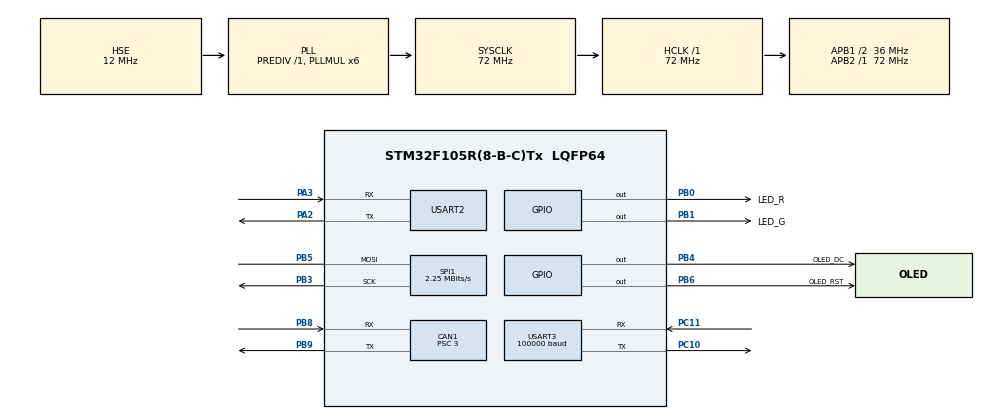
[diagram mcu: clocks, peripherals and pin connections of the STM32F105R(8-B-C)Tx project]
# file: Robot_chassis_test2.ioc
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CAN1.BS1=CAN_BS1_3TQ
CAN1.BS2=CAN_BS2_8TQ
CAN1.CalculateTimeBit=1000
CAN1.CalculateTimeQuantum=83.33333333333334
CAN1.Prescaler=3
Dma.Request0=USART3_RX
Dma.USART3_RX.0.Direction=DMA_PERIPH_TO_MEMORY
Dma.USART3_RX.0.Instance=DMA1_Channel3
Dma.USART3_RX.0.MemDataAlignment=DMA_MDATAALIGN_BYTE
Dma.USART3_RX.0.MemInc=DMA_MINC_ENABLE
Dma.USART3_RX.0.Mode=DMA_NORMAL
Dma.USART3_RX.0.PeriphDataAlignment=DMA_PDATAALIGN_BYTE
Dma.USART3_RX.0.PeriphInc=DMA_PINC_DISABLE
Dma.USART3_RX.0.Priority=DMA_PRIORITY_LOW
FREERTOS.Tasks01=vInitial_Task,2,128,Initial_Task,Default,NULL,Dynamic,NULL,NULL;vUser_Task,-1,128,User_Task,Default,NULL,Dynamic,NULL,NULL;vStartTask,-2,128,StartTask,Default,NULL,Dynamic,NULL,NULL;vChassis_Task,1,128,Chassis_Task,Default,NULL,Dynamic,NULL,NULL
Mcu.Family=STM32F1
Mcu.Name=STM32F105R(8-B-C)Tx
Mcu.Package=LQFP64
NVIC.CAN1_RX0_IRQn=true\:13\:0\:true\:false\:true\:true\:true\:true
NVIC.CAN1_TX_IRQn=true\:13\:0\:true\:false\:true\:true\:true\:true
NVIC.DMA1_Channel3_IRQn=true\:5\:0\:false\:false\:true\:true\:false\:true
NVIC.PriorityGroup=NVIC_PRIORITYGROUP_4
NVIC.USART3_IRQn=true\:6\:0\:true\:false\:true\:true\:true\:true
PA13.Mode=Serial_Wire
PA13.Signal=SYS_JTMS-SWDIO
PA14.Mode=Serial_Wire
PA14.Signal=SYS_JTCK-SWCLK
PA2.Mode=Asynchronous
PA2.Signal=USART2_TX
PA3.Mode=Asynchronous
PA3.Signal=USART2_RX
PB0.GPIO_Label=LED_R
PB0.Signal=GPIO_Output
PB1.GPIO_Label=LED_G
PB1.Signal=GPIO_Output
PB3.Mode=Simplex_Bidirectional_Master
PB3.Signal=SPI1_SCK
PB4.GPIO_Label=OLED_DC
PB4.Signal=GPIO_Output
PB5.Mode=Simplex_Bidirectional_Master
PB5.Signal=SPI1_MOSI
PB6.GPIO_Label=OLED_RST
PB6.Signal=GPIO_Output
PB8.Mode=Master
PB8.Signal=CAN1_RX
PB9.Mode=Master
PB9.Signal=CAN1_TX
PC10.Mode=Asynchronous
PC10.Signal=USART3_TX
PC11.Mode=Asynchronous
PC11.Signal=USART3_RX
PD0-OSC_IN.Mode=HSE-External-Oscillator
PD0-OSC_IN.Signal=RCC_OSC_IN
PD1-OSC_OUT.Mode=HSE-External-Oscillator
PD1-OSC_OUT.Signal=RCC_OSC_OUT
ProjectManager.HeapSize=0x200
ProjectManager.StackSize=0x400
ProjectManager.TargetToolchain=MDK-ARM V5
RCC.AHBFreq_Value=72000000
RCC.APB1CLKDivider=RCC_HCLK_DIV2
RCC.APB1Freq_Value=36000000
RCC.APB1TimFreq_Value=72000000
RCC.APB2Freq_Value=72000000
RCC.APB2TimFreq_Value=72000000
RCC.HCLKFreq_Value=72000000
RCC.HSE_VALUE=12000000
RCC.PLLMUL=RCC_PLL_MUL6
RCC.PLLSourceVirtual=RCC_PLLSOURCE_HSE
RCC.SYSCLKFreq_VALUE=72000000
RCC.SYSCLKSource=RCC_SYSCLKSOURCE_PLLCLK
RCC.USBFreq_Value=48000000
SPI1.BaudRatePrescaler=SPI_BAUDRATEPRESCALER_32
SPI1.CalculateBaudRate=2.25 MBits/s
SPI1.Direction=SPI_DIRECTION_1LINE
SPI1.Mode=SPI_MODE_MASTER
SPI1.VirtualType=VM_MASTER
USART2.VirtualMode=VM_ASYNC
USART3.BaudRate=100000
USART3.VirtualMode=VM_ASYNC
VP_FREERTOS_VS_CMSIS_V1.Mode=CMSIS_V1
board=custom

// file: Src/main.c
/* USER CODE BEGIN Header */
/**
  ******************************************************************************
  * @file           : main.c
  * @brief          : Main program body
  ******************************************************************************
  * @attention
  *
  * <h2><center>&copy; Copyright (c) 2019 STMicroelectronics.
  * All rights reserved.</center></h2>
  *
  * This software component is licensed by ST under Ultimate Liberty license
  * SLA0044, the "License"; You may not use this file except in compliance with
  * the License. You may obtain a copy of the License at:
  *                             www.st.com/SLA0044
  *
  ******************************************************************************
  */
/* USER CODE END Header */

#include "main.h"
#include "cmsis_os.h"
#include "can.h"
#include "dma.h"
#include "spi.h"
#include "usart.h"
#include "gpio.h"

/* USER CODE BEGIN Includes */
#include "Chassis_Task.h"
/* USER CODE END Includes */

void SystemClock_Config(void);
void MX_FREERTOS_Init(void);

int main(void)
{

  /* MCU Configuration--------------------------------------------------------*/

  /* Reset of all peripherals, Initializes the Flash interface and the Systick. */
  HAL_Init();

  /* Configure the system clock */
  SystemClock_Config();

  /* Initialize all configured peripherals */
  MX_GPIO_Init();
  MX_DMA_Init();
  MX_SPI1_Init();
  MX_USART2_UART_Init();
  MX_USART3_UART_Init();
  MX_CAN1_Init();
  /* USER CODE BEGIN 2 */

	can_user_init(&hcan1);															//can设备准备好
	HAL_UART_Receive_IT_IDLE(&huart3,UART_Buffer,100);   //启动串口接收

//	for (uint8_t i = 0; i < 7; i++)
//  {
//    pid_init(&motor_pid[i], 1.5, 0.1, 0, 30000, 30000); //init pid parameter, kp=40, ki=3, kd=0, output limit = 30000
//  }
  /* USER CODE END 2 */

  /* Call init function for freertos objects (in freertos.c) */
  MX_FREERTOS_Init();

  /* Start scheduler */
  osKernelStart();

  /* We should never get here as control is now taken by the scheduler */

  /* Infinite loop */
  while (1)
  {

  }
}

void SystemClock_Config(void)
{
  RCC_OscInitTypeDef RCC_OscInitStruct = {0};
  RCC_ClkInitTypeDef RCC_ClkInitStruct = {0};

  /** Initializes the CPU, AHB and APB busses clocks
  */
  RCC_OscInitStruct.OscillatorType = RCC_OSCILLATORTYPE_HSE;
  RCC_OscInitStruct.HSEState = RCC_HSE_ON;
  RCC_OscInitStruct.HSEPredivValue = RCC_HSE_PREDIV_DIV1;
  RCC_OscInitStruct.HSIState = RCC_HSI_ON;
  RCC_OscInitStruct.Prediv1Source = RCC_PREDIV1_SOURCE_HSE;
  RCC_OscInitStruct.PLL.PLLState = RCC_PLL_ON;
  RCC_OscInitStruct.PLL.PLLSource = RCC_PLLSOURCE_HSE;
  RCC_OscInitStruct.PLL.PLLMUL = RCC_PLL_MUL6;
  RCC_OscInitStruct.PLL2.PLL2State = RCC_PLL_NONE;
  if (HAL_RCC_OscConfig(&RCC_OscInitStruct) != HAL_OK)
  {
    Error_Handler();
  }
  /** Initializes the CPU, AHB and APB busses clocks
  */
  RCC_ClkInitStruct.ClockType = RCC_CLOCKTYPE_HCLK|RCC_CLOCKTYPE_SYSCLK
                              |RCC_CLOCKTYPE_PCLK1|RCC_CLOCKTYPE_PCLK2;
  RCC_ClkInitStruct.SYSCLKSource = RCC_SYSCLKSOURCE_PLLCLK;
  RCC_ClkInitStruct.AHBCLKDivider = RCC_SYSCLK_DIV1;
  RCC_ClkInitStruct.APB1CLKDivider = RCC_HCLK_DIV2;
  RCC_ClkInitStruct.APB2CLKDivider = RCC_HCLK_DIV1;

  if (HAL_RCC_ClockConfig(&RCC_ClkInitStruct, FLASH_LATENCY_2) != HAL_OK)
  {
    Error_Handler();
  }
  /** Configure the Systick interrupt time
  */
  __HAL_RCC_PLLI2S_ENABLE();
}

void Error_Handler(void)
{
}

/************************ (C) COPYRIGHT STMicroelectronics *****END OF FILE****/

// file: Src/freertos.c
/* USER CODE BEGIN Header */
/**
  ******************************************************************************
  * File Name          : freertos.c
  * Description        : Code for freertos applications
  ******************************************************************************
  * @attention
  *
  * <h2><center>&copy; Copyright (c) 2019 STMicroelectronics.
  * All rights reserved.</center></h2>
  *
  * This software component is licensed by ST under Ultimate Liberty license
  * SLA0044, the "License"; You may not use this file except in compliance with
  * the License. You may obtain a copy of the License at:
  *                             www.st.com/SLA0044
  *
  ******************************************************************************
  */
/* USER CODE END Header */

#include "FreeRTOS.h"
#include "task.h"
#include "main.h"
#include "cmsis_os.h"

/* USER CODE BEGIN Includes */
#include "Initial_Task.h"
#include "User_task.h"
#include "Chassis_Task.h"
/* USER CODE END Includes */

osThreadId vInitial_TaskHandle;
osThreadId vUser_TaskHandle;
osThreadId vStartTaskHandle;
osThreadId vChassis_TaskHandle;

void Initial_Task(void const * argument);
void User_Task(void const * argument);
void StartTask(void const * argument);
void Chassis_Task(void const * argument);

void MX_FREERTOS_Init(void); /* (MISRA C 2004 rule 8.1) */

void MX_FREERTOS_Init(void) {

  /* Create the thread(s) */
  /* definition and creation of vInitial_Task */
//  osThreadDef(vInitial_Task, Initial_Task, osPriorityHigh, 0, 128);
//  vInitial_TaskHandle = osThreadCreate(osThread(vInitial_Task), NULL);

  /* definition and creation of vUser_Task */
//  osThreadDef(vUser_Task, User_Task, osPriorityBelowNormal, 0, 128);
//  vUser_TaskHandle = osThreadCreate(osThread(vUser_Task), NULL);

  /* definition and creation of vStartTask */
  osThreadDef(vStartTask, StartTask, osPriorityLow, 0, 128);
  vStartTaskHandle = osThreadCreate(osThread(vStartTask), NULL);

  /* definition and creation of vChassis_Task */
//  osThreadDef(vChassis_Task, Chassis_Task, osPriorityAboveNormal, 0, 128);
//  vChassis_TaskHandle = osThreadCreate(osThread(vChassis_Task), NULL);

  /* USER CODE BEGIN RTOS_THREADS */
  /* add threads, ... */
	printf("All Task is ready!\r\n");
  /* USER CODE END RTOS_THREADS */

}

//void Initial_Task(void const * argument)
//{

//  /* USER CODE BEGIN Initial_Task */
////  /* Infinite loop */
////  for(;;)
////  {
////    osDelay(1);
////  }
//  /* USER CODE END Initial_Task */
//}

//void User_Task(void const * argument)
//{
//  /* USER CODE BEGIN User_Task */
////  /* Infinite loop */
////  for(;;)
////  {
////    osDelay(1);
////  }
//  /* USER CODE END User_Task */
//}

void StartTask(void const * argument)
{
  /* USER CODE BEGIN StartTask */
	portENTER_CRITICAL();
	/************初始化任务**************/
	osThreadDef(vInitial_Task, Initial_Task, osPriorityHigh, 0, 128);
  vInitial_TaskHandle = osThreadCreate(osThread(vInitial_Task), NULL);

	/************底盘任务****************/
	osThreadDef(vChassis_Task, Chassis_Task, osPriorityAboveNormal, 0, 128);
  vChassis_TaskHandle = osThreadCreate(osThread(vChassis_Task), NULL);

	/************自定义任务**************/
  /* definition and creation of vUser_Task */
//  osThreadDef(vUser_Task, User_Task, osPriorityRealtime, 0, 128);
//  vUser_TaskHandle = osThreadCreate(osThread(vUser_Task), NULL);

	vTaskDelete(vStartTaskHandle); //删除开始任务
  portEXIT_CRITICAL();						//退出临界区
  /* Infinite loop */
  for(;;)
  {
    osDelay(1);
  }
  /* USER CODE END StartTask */
}

//void Chassis_Task(void const * argument)
//{
//  /* USER CODE BEGIN Chassis_Task */
////  /* Infinite loop */
////  for(;;)
////  {
////    osDelay(1);
////  }
//  /* USER CODE END Chassis_Task */
//}

/************************ (C) COPYRIGHT STMicroelectronics *****END OF FILE****/
